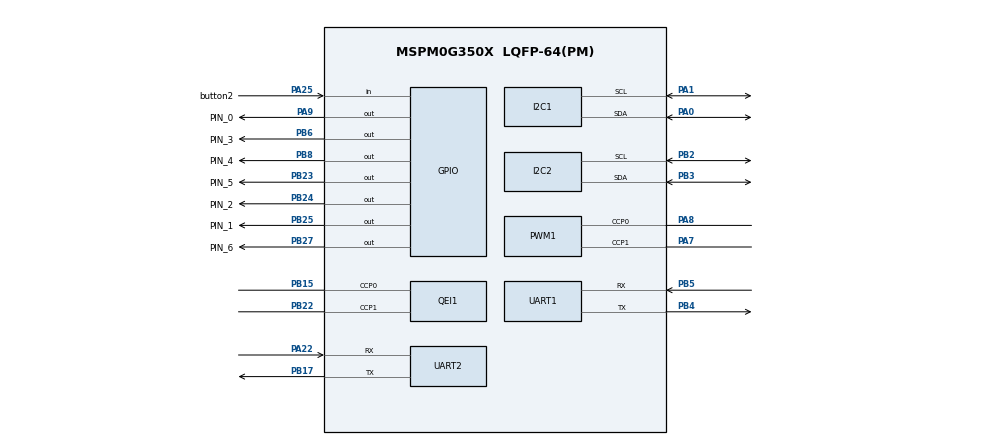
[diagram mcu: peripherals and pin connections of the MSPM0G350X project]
/**
 * @cliArgs --device "MSPM0G350X" --part "Default" --package "LQFP-64(PM)" --product "mspm0_sdk@2.10.00.04"
 * @versions {"tool":"1.26.2+4477"}
 */

/**
 * Import the modules used in this configuration.
 */
const GPIO   = scripting.addModule("/ti/driverlib/GPIO", {}, false);
const GPIO1  = GPIO.addInstance();
const GPIO2  = GPIO.addInstance();
const GPIO3  = GPIO.addInstance();
const GPIO4  = GPIO.addInstance();
const I2C    = scripting.addModule("/ti/driverlib/I2C", {}, false);
const I2C1   = I2C.addInstance();
const I2C2   = I2C.addInstance();
const PWM    = scripting.addModule("/ti/driverlib/PWM", {}, false);
const PWM1   = PWM.addInstance();
const QEI    = scripting.addModule("/ti/driverlib/QEI", {}, false);
const QEI1   = QEI.addInstance();
const SYSCTL = scripting.addModule("/ti/driverlib/SYSCTL");
const TIMER  = scripting.addModule("/ti/driverlib/TIMER", {}, false);
const TIMER1 = TIMER.addInstance();
const UART   = scripting.addModule("/ti/driverlib/UART", {}, false);
const UART1  = UART.addInstance();
const UART2  = UART.addInstance();

/**
 * Write custom configuration values to the imported modules.
 */
GPIO1.$name                          = "sound";
GPIO1.associatedPins[0].$name        = "PIN_0";
GPIO1.associatedPins[0].initialValue = "SET";
GPIO1.associatedPins[0].pin.$assign  = "PA9";

const Board = scripting.addModule("/ti/driverlib/Board", {}, false);

GPIO2.$name                              = "button";
GPIO2.associatedPins.create(2);
GPIO2.associatedPins[0].$name            = "button1";
GPIO2.associatedPins[0].direction        = "INPUT";
GPIO2.associatedPins[0].internalResistor = "PULL_UP";
GPIO2.associatedPins[0].assignedPort     = "PORTA";
GPIO2.associatedPins[0].assignedPin      = "24";
GPIO2.associatedPins[0].ioStructure      = "SD";
GPIO2.associatedPins[1].$name            = "button2";
GPIO2.associatedPins[1].direction        = "INPUT";
GPIO2.associatedPins[1].internalResistor = "PULL_UP";
GPIO2.associatedPins[1].pin.$assign      = "PA25";

GPIO3.$name                         = "MotorSpeed";
GPIO3.associatedPins.create(2);
GPIO3.associatedPins[0].$name       = "PIN_1";
GPIO3.associatedPins[0].pin.$assign = "PB25";
GPIO3.associatedPins[1].$name       = "PIN_2";
GPIO3.associatedPins[1].pin.$assign = "PB24";

GPIO4.$name                         = "GPIO_MOTOR";
GPIO4.associatedPins.create(4);
GPIO4.associatedPins[0].$name       = "PIN_3";
GPIO4.associatedPins[0].pin.$assign = "PB6";
GPIO4.associatedPins[1].$name       = "PIN_4";
GPIO4.associatedPins[1].pin.$assign = "PB8";
GPIO4.associatedPins[2].$name       = "PIN_5";
GPIO4.associatedPins[2].pin.$assign = "PB23";
GPIO4.associatedPins[3].$name       = "PIN_6";
GPIO4.associatedPins[3].pin.$assign = "PB27";

I2C1.basicEnableController             = true;
I2C1.$name                             = "I2C";
I2C1.basicControllerBusSpeed           = 400000;
I2C1.advAnalogGlitchFilter             = "DISABLED";
I2C1.advControllerTXFIFOTRIG           = "BYTES_1";
I2C1.intController                     = ["ARBITRATION_LOST","NACK","RXFIFO_TRIGGER","RX_DONE","TX_DONE"];
I2C1.interruptPriority                 = "0";
I2C1.peripheral.$assign                = "I2C0";
I2C1.peripheral.sdaPin.$assign         = "PA0";
I2C1.peripheral.sclPin.$assign         = "PA1";
I2C1.sdaPinConfig.$name                = "ti_driverlib_gpio_GPIOPinGeneric0";
I2C1.sdaPinConfig.hideOutputInversion  = scripting.forceWrite(false);
I2C1.sdaPinConfig.onlyInternalResistor = scripting.forceWrite(false);
I2C1.sdaPinConfig.passedPeripheralType = scripting.forceWrite("Digital");
I2C1.sdaPinConfig.enableConfig         = true;
I2C1.sclPinConfig.$name                = "ti_driverlib_gpio_GPIOPinGeneric1";
I2C1.sclPinConfig.hideOutputInversion  = scripting.forceWrite(false);
I2C1.sclPinConfig.onlyInternalResistor = scripting.forceWrite(false);
I2C1.sclPinConfig.passedPeripheralType = scripting.forceWrite("Digital");
I2C1.sclPinConfig.enableConfig         = true;

I2C2.basicEnableController             = true;
I2C2.$name                             = "I2C_OLED";
I2C2.peripheral.$assign                = "I2C1";
I2C2.peripheral.sdaPin.$assign         = "PB3";
I2C2.peripheral.sclPin.$assign         = "PB2";
I2C2.sdaPinConfig.hideOutputInversion  = scripting.forceWrite(false);
I2C2.sdaPinConfig.onlyInternalResistor = scripting.forceWrite(false);
I2C2.sdaPinConfig.passedPeripheralType = scripting.forceWrite("Digital");
I2C2.sdaPinConfig.$name                = "ti_driverlib_gpio_GPIOPinGeneric10";
I2C2.sclPinConfig.hideOutputInversion  = scripting.forceWrite(false);
I2C2.sclPinConfig.onlyInternalResistor = scripting.forceWrite(false);
I2C2.sclPinConfig.passedPeripheralType = scripting.forceWrite("Digital");
I2C2.sclPinConfig.$name                = "ti_driverlib_gpio_GPIOPinGeneric11";

PWM1.$name                      = "PWM_0";
PWM1.pwmMode                    = "EDGE_ALIGN_UP";
PWM1.clockDivider               = 2;
PWM1.enableShadowLoad           = true;
PWM1.peripheral.$assign         = "TIMA0";
PWM1.peripheral.ccp0Pin.$assign = "PA8";
PWM1.peripheral.ccp1Pin.$assign = "PA7";
PWM1.PWM_CHANNEL_0.$name        = "ti_driverlib_pwm_PWMTimerCC0";
PWM1.PWM_CHANNEL_0.dutyCycle    = 50;
PWM1.PWM_CHANNEL_1.$name        = "ti_driverlib_pwm_PWMTimerCC1";
PWM1.PWM_CHANNEL_1.dutyCycle    = 50;
PWM1.ccp0PinConfig.$name        = "ti_driverlib_gpio_GPIOPinGeneric4";
PWM1.ccp1PinConfig.$name        = "ti_driverlib_gpio_GPIOPinGeneric5";

QEI1.$name                      = "QEI_0";
QEI1.peripheral.ccp0Pin.$assign = "PB15";
QEI1.peripheral.ccp1Pin.$assign = "PB22";
QEI1.ccp0PinConfig.$name        = "ti_driverlib_gpio_GPIOPinGeneric12";
QEI1.ccp1PinConfig.$name        = "ti_driverlib_gpio_GPIOPinGeneric13";

SYSCTL.forceDefaultClkConfig = true;
SYSCTL.clockTreeEn           = true;

TIMER1.$name             = "TIMER_0";
TIMER1.timerMode         = "PERIODIC_UP";
TIMER1.interrupts        = ["LOAD"];
TIMER1.timerClkPrescale  = 256;
TIMER1.timerPeriod       = "10ms";
TIMER1.interruptPriority = "1";

UART1.$name                            = "UART_1";
UART1.enabledInterrupts                = ["RX"];
UART1.targetBaudRate                   = 115200;
UART1.interruptPriority                = "0";
UART1.peripheral.$assign               = "UART1";
UART1.peripheral.rxPin.$assign         = "PB5";
UART1.peripheral.txPin.$assign         = "PB4";
UART1.txPinConfig.direction            = scripting.forceWrite("OUTPUT");
UART1.txPinConfig.hideOutputInversion  = scripting.forceWrite(false);
UART1.txPinConfig.onlyInternalResistor = scripting.forceWrite(false);
UART1.txPinConfig.passedPeripheralType = scripting.forceWrite("Digital");
UART1.txPinConfig.$name                = "ti_driverlib_gpio_GPIOPinGeneric2";
UART1.rxPinConfig.hideOutputInversion  = scripting.forceWrite(false);
UART1.rxPinConfig.onlyInternalResistor = scripting.forceWrite(false);
UART1.rxPinConfig.passedPeripheralType = scripting.forceWrite("Digital");
UART1.rxPinConfig.$name                = "ti_driverlib_gpio_GPIOPinGeneric3";
UART1.rxPinConfig.enableConfig         = true;
UART1.rxPinConfig.internalResistor     = "PULL_UP";

UART2.$name                            = "UART_2";
UART2.peripheral.$assign               = "UART2";
UART2.peripheral.rxPin.$assign         = "PA22";
UART2.peripheral.txPin.$assign         = "PB17";
UART2.txPinConfig.direction            = scripting.forceWrite("OUTPUT");
UART2.txPinConfig.hideOutputInversion  = scripting.forceWrite(false);
UART2.txPinConfig.onlyInternalResistor = scripting.forceWrite(false);
UART2.txPinConfig.passedPeripheralType = scripting.forceWrite("Digital");
UART2.txPinConfig.$name                = "ti_driverlib_gpio_GPIOPinGeneric6";
UART2.rxPinConfig.hideOutputInversion  = scripting.forceWrite(false);
UART2.rxPinConfig.onlyInternalResistor = scripting.forceWrite(false);
UART2.rxPinConfig.passedPeripheralType = scripting.forceWrite("Digital");
UART2.rxPinConfig.$name                = "ti_driverlib_gpio_GPIOPinGeneric7";

/**
 * Pinmux solution for unlocked pins/peripherals. This ensures that minor changes to the automatic solver in a future
 * version of the tool will not impact the pinmux you originally saw.  These lines can be completely deleted in order to
 * re-solve from scratch.
 */
Board.peripheral.$suggestSolution            = "DEBUGSS";
Board.peripheral.swclkPin.$suggestSolution   = "PA20";
Board.peripheral.swdioPin.$suggestSolution   = "PA19";
GPIO2.associatedPins[0].pin.$suggestSolution = "PA24";
QEI1.peripheral.$suggestSolution             = "TIMG8";
TIMER1.peripheral.$suggestSolution           = "TIMA1";
